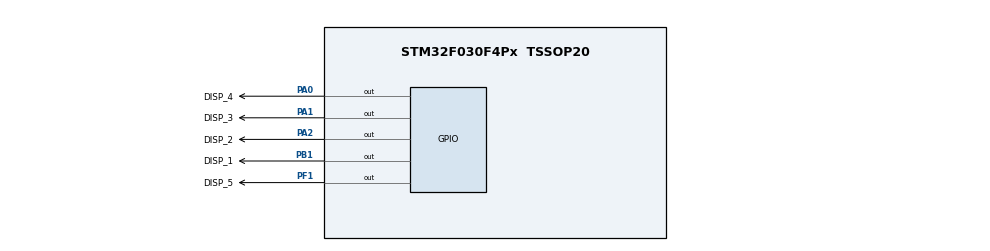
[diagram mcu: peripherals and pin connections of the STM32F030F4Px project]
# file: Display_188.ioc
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Mcu.Family=STM32F0
Mcu.Name=STM32F030F4Px
Mcu.Package=TSSOP20
NVIC.TIM1_BRK_UP_TRG_COM_IRQn=true\:0\:0\:false\:false\:true\:true\:true
PA0.GPIO_Label=DISP_4
PA0.Signal=GPIO_Output
PA1.GPIO_Label=DISP_3
PA1.Signal=GPIO_Output
PA13.Mode=Serial_Wire
PA13.Signal=SYS_SWDIO
PA14.Mode=Serial_Wire
PA14.Signal=SYS_SWCLK
PA2.GPIO_Label=DISP_2
PA2.Signal=GPIO_Output
PB1.GPIO_Label=DISP_1
PB1.Signal=GPIO_Output
PF1-OSC_OUT.GPIO_Label=DISP_5
PF1-OSC_OUT.Signal=GPIO_Output
ProjectManager.HeapSize=0x200
ProjectManager.StackSize=0x400
ProjectManager.TargetToolchain=STM32CubeIDE
RCC.AHBFreq_Value=48000000
RCC.APB1Freq_Value=48000000
RCC.APB1TimFreq_Value=48000000
RCC.HCLKFreq_Value=48000000
RCC.PLLMUL=RCC_PLL_MUL12
RCC.SYSCLKFreq_VALUE=48000000
RCC.SYSCLKSource=RCC_SYSCLKSOURCE_PLLCLK
TIM1.AutoReloadPreload=TIM_AUTORELOAD_PRELOAD_ENABLE
TIM1.Period=500
TIM1.Prescaler=48
VP_TIM1_VS_ClockSourceINT.Mode=Internal
board=custom

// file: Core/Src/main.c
/* USER CODE BEGIN Header */
/**
  ******************************************************************************
  * @file           : main.c
  * @brief          : Main program body
  ******************************************************************************
  * @attention
  *
  * Copyright (c) 2024 STMicroelectronics.
  * All rights reserved.
  *
  * This software is licensed under terms that can be found in the LICENSE file
  * in the root directory of this software component.
  * If no LICENSE file comes with this software, it is provided AS-IS.
  *
  ******************************************************************************
  */
/* USER CODE END Header */
#include "main.h"

/* USER CODE BEGIN PM */
#define DELAY 500
/* USER CODE END PM */

void SystemClock_Config(void);
static void MX_GPIO_Init(void);
static void MX_TIM1_Init(void);

int main(void)
{

  /* MCU Configuration--------------------------------------------------------*/

  /* Reset of all peripherals, Initializes the Flash interface and the Systick. */

  LL_APB1_GRP2_EnableClock(LL_APB1_GRP2_PERIPH_SYSCFG);
  LL_APB1_GRP1_EnableClock(LL_APB1_GRP1_PERIPH_PWR);

  /* System interrupt init*/
  /* SysTick_IRQn interrupt configuration */
  NVIC_SetPriority(SysTick_IRQn, 3);

  /* Configure the system clock */
  SystemClock_Config();

  /* Initialize all configured peripherals */
  MX_GPIO_Init();
  MX_TIM1_Init();
  /* USER CODE BEGIN 2 */
  LL_SYSTICK_EnableIT();
  DISP188_Init();
  /* USER CODE END 2 */

  /* Infinite loop */
  while (1)
  {
    DISP188_OutputText("  A");
    LL_mDelay(DELAY);
    DISP188_OutputText(" AB");
    LL_mDelay(DELAY);
    DISP188_OutputText(" BC");
    LL_mDelay(DELAY);
    DISP188_OutputText(" CD");
    LL_mDelay(DELAY);
    DISP188_OutputText(" DE");
    LL_mDelay(DELAY);
    DISP188_OutputText(" EF");
    LL_mDelay(DELAY);
    DISP188_OutputText(" FH");
    LL_mDelay(DELAY);
    DISP188_OutputText(" HJ");
    LL_mDelay(DELAY);
    DISP188_OutputText(" JL");
    LL_mDelay(DELAY);
    DISP188_OutputText(" LN");
    LL_mDelay(DELAY);
    DISP188_OutputText(" NO");
    LL_mDelay(DELAY);
    DISP188_OutputText(" OP");
    LL_mDelay(DELAY);
    DISP188_OutputText(" PR");
    LL_mDelay(DELAY);
    DISP188_OutputText(" RT");
    LL_mDelay(DELAY);
    DISP188_OutputText(" TU");
    LL_mDelay(DELAY);
    DISP188_OutputText(" U-");
    LL_mDelay(DELAY);
    DISP188_OutputText(" --");
    LL_mDelay(DELAY);
    DISP188_OutputText(" - ");
    LL_mDelay(DELAY);
    DISP188_OutputText("  0");
    LL_mDelay(DELAY);
    DISP188_OutputText(" 01");
    LL_mDelay(DELAY);
    DISP188_OutputText(" 12");
    LL_mDelay(DELAY);
    DISP188_OutputText(" 23");
    LL_mDelay(DELAY);
    DISP188_OutputText(" 34");
    LL_mDelay(DELAY);
    DISP188_OutputText(" 45");
    LL_mDelay(DELAY);
    DISP188_OutputText(" 56");
    LL_mDelay(DELAY);
    DISP188_OutputText(" 67");
    LL_mDelay(DELAY);
    DISP188_OutputText(" 78");
    LL_mDelay(DELAY);
    DISP188_OutputText(" 89");
    LL_mDelay(DELAY);
    DISP188_OutputText(" 9 ");
    LL_mDelay(DELAY);
    DISP188_OutputText("9  ");
    LL_mDelay(DELAY);
    DISP188_OutputText("   ");
    LL_mDelay(DELAY);

    for (uint8_t i = 0; i < 200; i++)
    {

      DISP188_OutputNumber(i);
      LL_mDelay(50);
    }
    LL_mDelay(500);
  }
}

void SystemClock_Config(void)
{
  LL_FLASH_SetLatency(LL_FLASH_LATENCY_1);
  while(LL_FLASH_GetLatency() != LL_FLASH_LATENCY_1)
  {
  }
  LL_RCC_HSI_Enable();

   /* Wait till HSI is ready */
  while(LL_RCC_HSI_IsReady() != 1)
  {

  }
  LL_RCC_HSI_SetCalibTrimming(16);
  LL_RCC_PLL_ConfigDomain_SYS(LL_RCC_PLLSOURCE_HSI_DIV_2, LL_RCC_PLL_MUL_12);
  LL_RCC_PLL_Enable();

   /* Wait till PLL is ready */
  while(LL_RCC_PLL_IsReady() != 1)
  {

  }
  LL_RCC_SetAHBPrescaler(LL_RCC_SYSCLK_DIV_1);
  LL_RCC_SetAPB1Prescaler(LL_RCC_APB1_DIV_1);
  LL_RCC_SetSysClkSource(LL_RCC_SYS_CLKSOURCE_PLL);

   /* Wait till System clock is ready */
  while(LL_RCC_GetSysClkSource() != LL_RCC_SYS_CLKSOURCE_STATUS_PLL)
  {

  }
  LL_Init1msTick(48000000);
  LL_SetSystemCoreClock(48000000);
}

static void MX_TIM1_Init(void)
{

  LL_TIM_InitTypeDef TIM_InitStruct = {0};

  /* Peripheral clock enable */
  LL_APB1_GRP2_EnableClock(LL_APB1_GRP2_PERIPH_TIM1);

  /* TIM1 interrupt Init */
  NVIC_SetPriority(TIM1_BRK_UP_TRG_COM_IRQn, 0);
  NVIC_EnableIRQ(TIM1_BRK_UP_TRG_COM_IRQn);

  TIM_InitStruct.Prescaler = 48;
  TIM_InitStruct.CounterMode = LL_TIM_COUNTERMODE_UP;
  TIM_InitStruct.Autoreload = 500;
  TIM_InitStruct.ClockDivision = LL_TIM_CLOCKDIVISION_DIV1;
  TIM_InitStruct.RepetitionCounter = 0;
  LL_TIM_Init(TIM1, &TIM_InitStruct);
  LL_TIM_EnableARRPreload(TIM1);
  LL_TIM_SetClockSource(TIM1, LL_TIM_CLOCKSOURCE_INTERNAL);
  LL_TIM_SetTriggerOutput(TIM1, LL_TIM_TRGO_RESET);
  LL_TIM_DisableMasterSlaveMode(TIM1);

}

static void MX_GPIO_Init(void)
{
  LL_GPIO_InitTypeDef GPIO_InitStruct = {0};

  /* GPIO Ports Clock Enable */
  LL_AHB1_GRP1_EnableClock(LL_AHB1_GRP1_PERIPH_GPIOF);
  LL_AHB1_GRP1_EnableClock(LL_AHB1_GRP1_PERIPH_GPIOA);
  LL_AHB1_GRP1_EnableClock(LL_AHB1_GRP1_PERIPH_GPIOB);

  /**/
  LL_GPIO_ResetOutputPin(GPIOF, LL_GPIO_PIN_1);

  /**/
  LL_GPIO_ResetOutputPin(GPIOA, LL_GPIO_PIN_0);

  /**/
  LL_GPIO_ResetOutputPin(GPIOA, LL_GPIO_PIN_1);

  /**/
  LL_GPIO_ResetOutputPin(GPIOA, LL_GPIO_PIN_2);

  /**/
  LL_GPIO_ResetOutputPin(GPIOB, LL_GPIO_PIN_1);

  /**/
  GPIO_InitStruct.Pin = LL_GPIO_PIN_1;
  GPIO_InitStruct.Mode = LL_GPIO_MODE_OUTPUT;
  GPIO_InitStruct.Speed = LL_GPIO_SPEED_FREQ_LOW;
  GPIO_InitStruct.OutputType = LL_GPIO_OUTPUT_PUSHPULL;
  GPIO_InitStruct.Pull = LL_GPIO_PULL_NO;
  LL_GPIO_Init(GPIOF, &GPIO_InitStruct);

  /**/
  GPIO_InitStruct.Pin = LL_GPIO_PIN_0;
  GPIO_InitStruct.Mode = LL_GPIO_MODE_OUTPUT;
  GPIO_InitStruct.Speed = LL_GPIO_SPEED_FREQ_LOW;
  GPIO_InitStruct.OutputType = LL_GPIO_OUTPUT_PUSHPULL;
  GPIO_InitStruct.Pull = LL_GPIO_PULL_NO;
  LL_GPIO_Init(GPIOA, &GPIO_InitStruct);

  /**/
  GPIO_InitStruct.Pin = LL_GPIO_PIN_1;
  GPIO_InitStruct.Mode = LL_GPIO_MODE_OUTPUT;
  GPIO_InitStruct.Speed = LL_GPIO_SPEED_FREQ_LOW;
  GPIO_InitStruct.OutputType = LL_GPIO_OUTPUT_PUSHPULL;
  GPIO_InitStruct.Pull = LL_GPIO_PULL_NO;
  LL_GPIO_Init(GPIOA, &GPIO_InitStruct);

  /**/
  GPIO_InitStruct.Pin = LL_GPIO_PIN_2;
  GPIO_InitStruct.Mode = LL_GPIO_MODE_OUTPUT;
  GPIO_InitStruct.Speed = LL_GPIO_SPEED_FREQ_LOW;
  GPIO_InitStruct.OutputType = LL_GPIO_OUTPUT_PUSHPULL;
  GPIO_InitStruct.Pull = LL_GPIO_PULL_NO;
  LL_GPIO_Init(GPIOA, &GPIO_InitStruct);

  /**/
  GPIO_InitStruct.Pin = LL_GPIO_PIN_1;
  GPIO_InitStruct.Mode = LL_GPIO_MODE_OUTPUT;
  GPIO_InitStruct.Speed = LL_GPIO_SPEED_FREQ_LOW;
  GPIO_InitStruct.OutputType = LL_GPIO_OUTPUT_PUSHPULL;
  GPIO_InitStruct.Pull = LL_GPIO_PULL_NO;
  LL_GPIO_Init(GPIOB, &GPIO_InitStruct);

}

void Error_Handler(void)
{
  __disable_irq();
  while (1)
  {
  }
}
